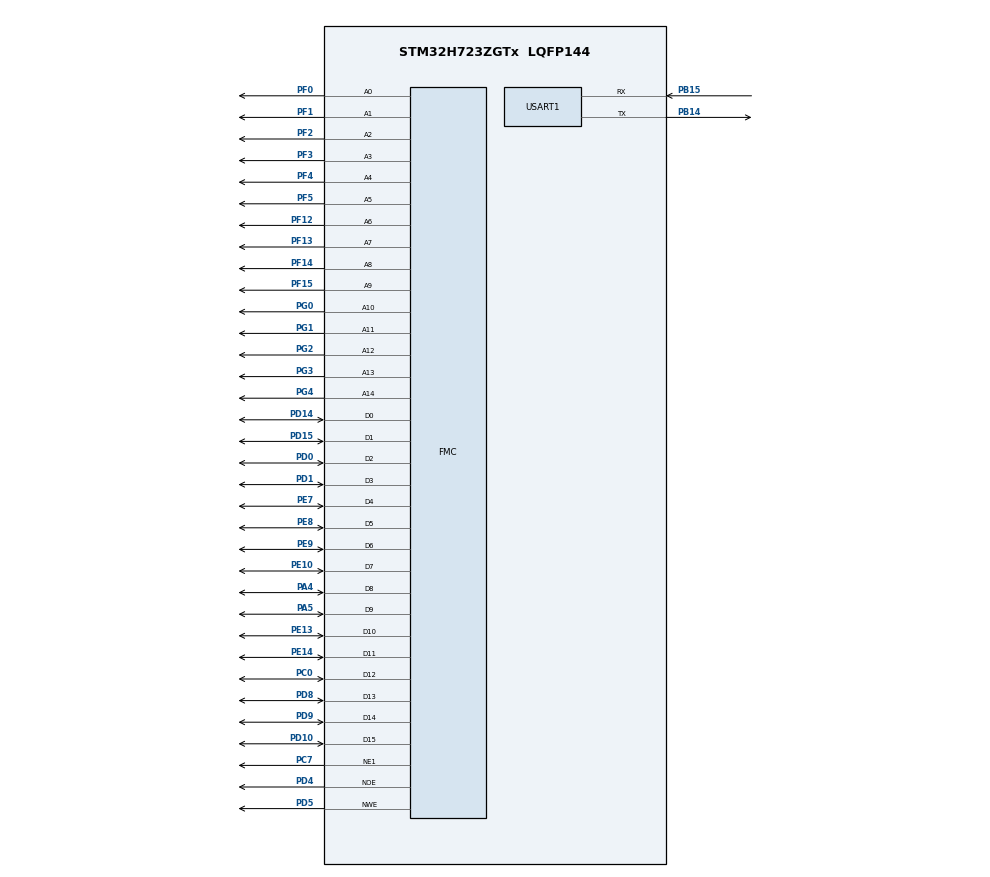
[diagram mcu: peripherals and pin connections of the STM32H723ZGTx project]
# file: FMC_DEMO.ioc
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CORTEX_M7.AccessPermission_Spec=MPU_REGION_FULL_ACCESS
CORTEX_M7.BaseAddress_Spec=0x60000000
CORTEX_M7.CPU_DCache=Enabled
CORTEX_M7.CPU_ICache=Enabled
CORTEX_M7.MPU_Control=MPU_HFNMI_PRIVDEF
CORTEX_M7.Size_Spec=MPU_REGION_SIZE_256MB
CORTEX_M7.default_mode_Activation=1
FMC.AddressSetupTime1=4
FMC.BusTurnAroundDuration1=2
FMC.DataSetupTime1=3
FMC.WriteFifo1=FMC_WRITE_FIFO_DISABLE
FMC.WriteFifo2=FMC_WRITE_FIFO_DISABLE
FMC.WriteFifo3=FMC_WRITE_FIFO_DISABLE
FMC.WriteFifo4=FMC_WRITE_FIFO_DISABLE
FMC.WriteOperation1=FMC_WRITE_OPERATION_ENABLE
Mcu.Family=STM32H7
Mcu.Name=STM32H723ZGTx
Mcu.Package=LQFP144
NVIC.PriorityGroup=NVIC_PRIORITYGROUP_4
NVIC.USART1_IRQn=true\:0\:0\:false\:false\:true\:true\:true\:true
PA4.Signal=FMC_D8_DA8
PA5.Signal=FMC_D9_DA9
PB14.Mode=Asynchronous
PB14.Signal=USART1_TX
PB15.Mode=Asynchronous
PB15.Signal=USART1_RX
PC0.Signal=FMC_D12_DA12
PC7.Mode=NorPsramChipSelect1_1
PC7.Signal=FMC_NE1
PD0.Signal=FMC_D2_DA2
PD1.Signal=FMC_D3_DA3
PD10.Signal=FMC_D15_DA15
PD14.Signal=FMC_D0_DA0
PD15.Signal=FMC_D1_DA1
PD4.Signal=FMC_NOE
PD5.Signal=FMC_NWE
PD8.Signal=FMC_D13_DA13
PD9.Signal=FMC_D14_DA14
PE10.Signal=FMC_D7_DA7
PE13.Signal=FMC_D10_DA10
PE14.Signal=FMC_D11_DA11
PE7.Signal=FMC_D4_DA4
PE8.Signal=FMC_D5_DA5
PE9.Signal=FMC_D6_DA6
PF0.Signal=FMC_A0
PF1.Signal=FMC_A1
PF12.Signal=FMC_A6
PF13.Signal=FMC_A7
PF14.Signal=FMC_A8
PF15.Signal=FMC_A9
PF2.Signal=FMC_A2
PF3.Signal=FMC_A3
PF4.Signal=FMC_A4
PF5.Signal=FMC_A5
PG0.Signal=FMC_A10
PG1.Signal=FMC_A11
PG2.Signal=FMC_A12
PG3.Signal=FMC_A13
PG4.Signal=FMC_A14_BA0
ProjectManager.HeapSize=0x200
ProjectManager.StackSize=0x400
ProjectManager.TargetToolchain=MDK-ARM V5.32
RCC.ADCFreq_Value=129000000
RCC.APB1Freq_Value=17187500
RCC.APB2Freq_Value=17187500
RCC.APB3Freq_Value=17187500
RCC.APB4Freq_Value=17187500
RCC.CortexFreq_Value=68750000
RCC.Cortex_Div=SYSTICK_CLKSOURCE_HCLK_DIV8
RCC.D1PPRE=RCC_APB3_DIV16
RCC.D2PPRE1=RCC_APB1_DIV16
RCC.D2PPRE2=RCC_APB2_DIV16
RCC.D3PPRE=RCC_APB4_DIV16
RCC.DIVN1=275
RCC.DIVP1=1
RCC.DIVQ1=5
RCC.FMCCLockSelection=RCC_FMCCLKSOURCE_PLL
RCC.HCLKFreq_Value=275000000
RCC.HPRE=RCC_HCLK_DIV2
RCC.PLLFRACN=0
RCC.SYSCLKFreq_VALUE=550000000
RCC.SYSCLKSource=RCC_SYSCLKSOURCE_PLLCLK
RCC.USBFreq_Value=110000000
SH.FMC_A0.0=FMC_A0,15b-a1
SH.FMC_A1.0=FMC_A1,15b-a1
SH.FMC_A10.0=FMC_A10,15b-a1
SH.FMC_A11.0=FMC_A11,15b-a1
SH.FMC_A12.0=FMC_A12,15b-a1
SH.FMC_A13.0=FMC_A13,15b-a1
SH.FMC_A14_BA0.0=FMC_A14,15b-a1
SH.FMC_A2.0=FMC_A2,15b-a1
SH.FMC_A3.0=FMC_A3,15b-a1
SH.FMC_A4.0=FMC_A4,15b-a1
SH.FMC_A5.0=FMC_A5,15b-a1
SH.FMC_A6.0=FMC_A6,15b-a1
SH.FMC_A7.0=FMC_A7,15b-a1
SH.FMC_A8.0=FMC_A8,15b-a1
SH.FMC_A9.0=FMC_A9,15b-a1
SH.FMC_D0_DA0.0=FMC_D0,16b-d1
SH.FMC_D10_DA10.0=FMC_D10,16b-d1
SH.FMC_D11_DA11.0=FMC_D11,16b-d1
SH.FMC_D12_DA12.0=FMC_D12,16b-d1
SH.FMC_D13_DA13.0=FMC_D13,16b-d1
SH.FMC_D14_DA14.0=FMC_D14,16b-d1
SH.FMC_D15_DA15.0=FMC_D15,16b-d1
SH.FMC_D1_DA1.0=FMC_D1,16b-d1
SH.FMC_D2_DA2.0=FMC_D2,16b-d1
SH.FMC_D3_DA3.0=FMC_D3,16b-d1
SH.FMC_D4_DA4.0=FMC_D4,16b-d1
SH.FMC_D5_DA5.0=FMC_D5,16b-d1
SH.FMC_D6_DA6.0=FMC_D6,16b-d1
SH.FMC_D7_DA7.0=FMC_D7,16b-d1
SH.FMC_D8_DA8.0=FMC_D8,16b-d1
SH.FMC_D9_DA9.0=FMC_D9,16b-d1
SH.FMC_NOE.0=FMC_NOE,Sram1
SH.FMC_NWE.0=FMC_NWE,Sram1
USART1.VirtualMode-Asynchronous=VM_ASYNC
VP_MEMORYMAP_VS_MEMORYMAP.Mode=CurAppReg
board=custom

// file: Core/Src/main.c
/* USER CODE BEGIN Header */
/**
  ******************************************************************************
  * @file           : main.c
  * @brief          : STM32H7 + FPGA + AD9740 Arbitrary Waveform Generator
  ******************************************************************************
  */
/* USER CODE END Header */
#include "main.h"
#include "usart.h"
#include "gpio.h"
#include "fmc.h"

/* USER CODE BEGIN Includes */
#include "app_awg.h"
/* USER CODE END Includes */

void SystemClock_Config(void);
static void MPU_Config(void);

int main(void)
{

  /* USER CODE BEGIN 1 */
  Board_InitEarly();
  /* USER CODE END 1 */

  /* MPU Configuration--------------------------------------------------------*/
  MPU_Config();

  /* Enable the CPU Cache */

  /* Enable I-Cache---------------------------------------------------------*/
  SCB_EnableICache();

  /* Enable D-Cache---------------------------------------------------------*/
  SCB_EnableDCache();

  /* MCU Configuration--------------------------------------------------------*/

  /* Reset of all peripherals, Initializes the Flash interface and the Systick. */
  HAL_Init();

  /* Configure the system clock */
  SystemClock_Config();

  /* Initialize all configured peripherals */
  MX_GPIO_Init();
  MX_FMC_Init();
  MX_USART1_UART_Init();
  /* USER CODE BEGIN 2 */
  APP_AWG_Init();
  /* USER CODE END 2 */

  /* Infinite loop */
  /* USER CODE BEGIN WHILE */
  while (1)
  {
    APP_AWG_Task();
    /* USER CODE END WHILE */

  }
}

void SystemClock_Config(void)
{
  RCC_OscInitTypeDef RCC_OscInitStruct = {0};
  RCC_ClkInitTypeDef RCC_ClkInitStruct = {0};

  /** Supply configuration update enable
  */
  HAL_PWREx_ConfigSupply(PWR_LDO_SUPPLY);

  /** Configure the main internal regulator output voltage
  */
  __HAL_PWR_VOLTAGESCALING_CONFIG(PWR_REGULATOR_VOLTAGE_SCALE0);

  while(!__HAL_PWR_GET_FLAG(PWR_FLAG_VOSRDY)) {}

  /** Initializes the RCC Oscillators according to the specified parameters
  * in the RCC_OscInitTypeDef structure.
  */
  RCC_OscInitStruct.OscillatorType = RCC_OSCILLATORTYPE_HSI;
  RCC_OscInitStruct.HSIState = RCC_HSI_DIV1;
  RCC_OscInitStruct.HSICalibrationValue = 64;
  RCC_OscInitStruct.PLL.PLLState = RCC_PLL_ON;
  RCC_OscInitStruct.PLL.PLLSource = RCC_PLLSOURCE_HSI;
  RCC_OscInitStruct.PLL.PLLM = 32;
  RCC_OscInitStruct.PLL.PLLN = 275;
  RCC_OscInitStruct.PLL.PLLP = 1;
  RCC_OscInitStruct.PLL.PLLQ = 5;
  RCC_OscInitStruct.PLL.PLLR = 2;
  RCC_OscInitStruct.PLL.PLLRGE = RCC_PLL1VCIRANGE_1;
  RCC_OscInitStruct.PLL.PLLVCOSEL = RCC_PLL1VCOWIDE;
  RCC_OscInitStruct.PLL.PLLFRACN = 0;
  if (HAL_RCC_OscConfig(&RCC_OscInitStruct) != HAL_OK)
  {
    Error_Handler();
  }

  /** Initializes the CPU, AHB and APB buses clocks
  */
  RCC_ClkInitStruct.ClockType = RCC_CLOCKTYPE_HCLK|RCC_CLOCKTYPE_SYSCLK
                              |RCC_CLOCKTYPE_PCLK1|RCC_CLOCKTYPE_PCLK2
                              |RCC_CLOCKTYPE_D3PCLK1|RCC_CLOCKTYPE_D1PCLK1;
  RCC_ClkInitStruct.SYSCLKSource = RCC_SYSCLKSOURCE_PLLCLK;
  RCC_ClkInitStruct.SYSCLKDivider = RCC_SYSCLK_DIV1;
  RCC_ClkInitStruct.AHBCLKDivider = RCC_HCLK_DIV2;
  RCC_ClkInitStruct.APB3CLKDivider = RCC_APB3_DIV16;
  RCC_ClkInitStruct.APB1CLKDivider = RCC_APB1_DIV16;
  RCC_ClkInitStruct.APB2CLKDivider = RCC_APB2_DIV16;
  RCC_ClkInitStruct.APB4CLKDivider = RCC_APB4_DIV16;

  if (HAL_RCC_ClockConfig(&RCC_ClkInitStruct, FLASH_LATENCY_3) != HAL_OK)
  {
    Error_Handler();
  }
}

 /* MPU Configuration */

void MPU_Config(void)
{
  MPU_Region_InitTypeDef MPU_InitStruct = {0};

  /* Disables the MPU */
  HAL_MPU_Disable();

  /** Initializes and configures the Region and the memory to be protected
  */
  MPU_InitStruct.Enable = MPU_REGION_ENABLE;
  MPU_InitStruct.Number = MPU_REGION_NUMBER0;
  MPU_InitStruct.BaseAddress = 0x60000000;
  MPU_InitStruct.Size = MPU_REGION_SIZE_256MB;
  MPU_InitStruct.SubRegionDisable = 0x87;
  MPU_InitStruct.TypeExtField = MPU_TEX_LEVEL0;
  MPU_InitStruct.AccessPermission = MPU_REGION_FULL_ACCESS;
  MPU_InitStruct.DisableExec = MPU_INSTRUCTION_ACCESS_DISABLE;
  MPU_InitStruct.IsShareable = MPU_ACCESS_SHAREABLE;
  MPU_InitStruct.IsCacheable = MPU_ACCESS_NOT_CACHEABLE;
  MPU_InitStruct.IsBufferable = MPU_ACCESS_NOT_BUFFERABLE;

  HAL_MPU_ConfigRegion(&MPU_InitStruct);
  /* Enables the MPU */
  HAL_MPU_Enable(MPU_HFNMI_PRIVDEF);

}

void Error_Handler(void)
{
  __disable_irq();
  while (1)
  {
  }
}
